# R5FSS0_CORE0_ECC_AGGR register map
Vendor: Texas Instruments
Peripheral module from a debugger description file (folder J7VCL).
Registers are 32-bit, access not given, reset 0x0 unless marked. A register's access mark holds for its fields unless they carry their own. Offsets are as the file gives them; lines under a group give offsets from that group; [hi:lo] are bit positions; {n}, {i} and the like mark numbered series; 'fields as' and 'values as' point back to an identical list; <NAME> marks a mode.

## R5FSS0_CORE0_ECC_AGGR
0x00 R5FSS_CPU0_REV ro reset 0x66A0E200 — Revision register.
  [31:0] REV — TI internal data. Identifies revision of peripheral.
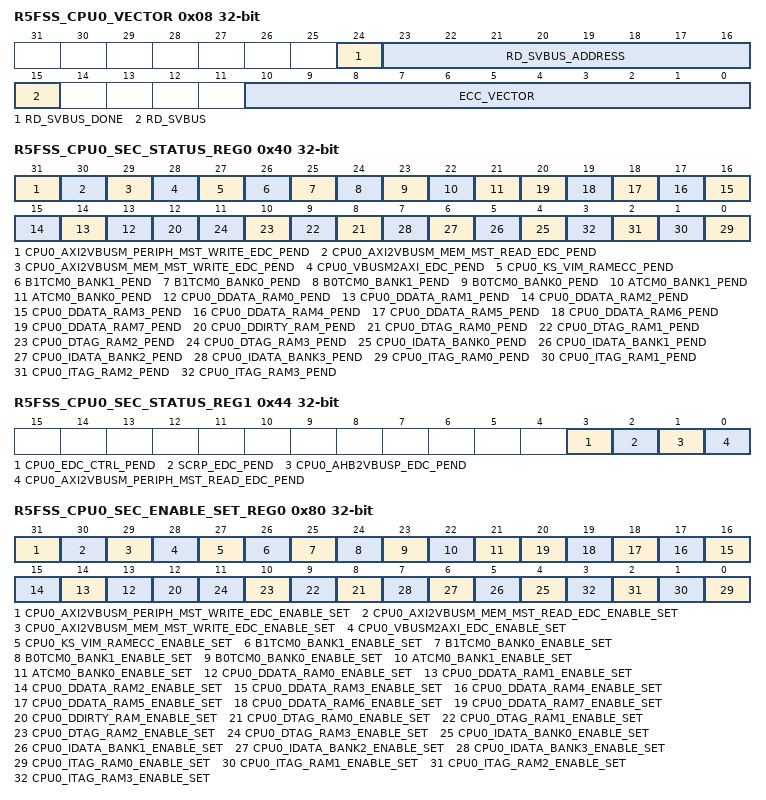
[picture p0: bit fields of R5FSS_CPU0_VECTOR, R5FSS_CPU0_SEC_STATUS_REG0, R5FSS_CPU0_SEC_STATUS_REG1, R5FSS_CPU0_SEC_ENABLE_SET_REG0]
0x08 R5FSS_CPU0_VECTOR — ECC vector register.
  [24] RD_SVBUS_DONE — Status to indicate if read on serial VBUS is complete, write of any value will clear this bit. (access RW1C)
  [23:16] RD_SVBUS_ADDRESS rw — Read address.
  [15] RD_SVBUS — Write 1 to trigger a read on the serial VBUS. (access RW1S)
  [10:0] ECC_VECTOR rw — Value written to select the corresponding ECC RAM for control or status.
0x0C R5FSS_CPU0_STAT ro reset 0x24 — Misc status register.
  [10:0] NUM_RAMS — Indicates the number of RAMS serviced by the ECC aggregator.
0x3C R5FSS_CPU0_SEC_EOI_REG — SEC EOI register. The EOI register is used to re-trigger the pulse interrupt signal to ensure that any nested interrupt events are serviced. The software interrupt handler must write to the EOI register at the end of the current interrupt processing routine, so that new events can re-trigger the pulse interrupt signal again. For level interrupt signals the EOI register is not functional and must not be used.
  [0] EOI_WR — EOI value. (access RW1S)
0x40 R5FSS_CPU0_SEC_STATUS_REG0 — SEC interrupt status register 0.
  [31] CPU0_AXI2VBUSM_PERIPH_MST_WRITE_EDC_PEND — Interrupt pending status for cpu0_axi2vbusm_periph_mst_write_edc_pend (access RW1S)
  [30] CPU0_AXI2VBUSM_MEM_MST_READ_EDC_PEND — Interrupt pending status for cpu0_axi2vbusm_mem_mst_read_edc_pend (access RW1S)
  [29] CPU0_AXI2VBUSM_MEM_MST_WRITE_EDC_PEND — Interrupt pending status for cpu0_axi2vbusm_mem_mst_write_edc_pend (access RW1S)
  [28] CPU0_VBUSM2AXI_EDC_PEND — Interrupt pending status for cpu0_vbusm2axi_edc_pend (access RW1S)
  [27] CPU0_KS_VIM_RAMECC_PEND — Interrupt pending status for cpu0_ks_vim_ramecc_pend (access RW1S)
  [26] B1TCM0_BANK1_PEND — Interrupt pending status for b1tcm0_bank1_pend (access RW1S)
  [25] B1TCM0_BANK0_PEND — Interrupt pending status for b1tcm0_bank0_pend (access RW1S)
  [24] B0TCM0_BANK1_PEND — Interrupt pending status for b0tcm0_bank1_pend (access RW1S)
  [23] B0TCM0_BANK0_PEND — Interrupt pending status for b0tcm0_bank0_pend (access RW1S)
  [22] ATCM0_BANK1_PEND — Interrupt pending status for atcm0_bank1_pend (access RW1S)
  [21] ATCM0_BANK0_PEND — Interrupt pending status for atcm0_bank0_pend (access RW1S)
  [n+13] CPU0_DDATA_RAM{n}_PEND (n=0..7) — Interrupt pending status for cpu0_ddata_ram{n}_pend (access RW1S)
  [12] CPU0_DDIRTY_RAM_PEND — Interrupt pending status for cpu0_ddirty_ram_pend (access RW1S)
  [n+8] CPU0_DTAG_RAM{n}_PEND (n=0..3) — Interrupt pending status for cpu0_dtag_ram{n}_pend (access RW1S)
  [n+4] CPU0_IDATA_BANK{n}_PEND (n=0..3) — Interrupt pending status for cpu0_idata_bank{n}_pend (access RW1S)
  [n] CPU0_ITAG_RAM{n}_PEND (n=0..3) — Interrupt pending status for cpu0_itag_ram{n}_pend (access RW1S)
0x44 R5FSS_CPU0_SEC_STATUS_REG1 — SEC interrupt status register 1.
  [3] CPU0_EDC_CTRL_PEND — Interrupt pending status for cpu0_edc_ctrl_pend (access RW1S)
  [2] SCRP_EDC_PEND — Interrupt pending status for scrp_edc_pend (access RW1S)
  [1] CPU0_AHB2VBUSP_EDC_PEND — Interrupt pending status for cpu0_ahb2vbusp_edc_pend (access RW1S)
  [0] CPU0_AXI2VBUSM_PERIPH_MST_READ_EDC_PEND — Interrupt pending status for cpu0_axi2vbusm_periph_mst_read_edc_pend (access RW1S)
0x80 R5FSS_CPU0_SEC_ENABLE_SET_REG0 — SEC Interrupt enable set register 0.
  [31] CPU0_AXI2VBUSM_PERIPH_MST_WRITE_EDC_ENABLE_SET — Interrupt enable set register for cpu0_axi2vbusm_periph_mst_write_edc_pend (access RW1S)
  [30] CPU0_AXI2VBUSM_MEM_MST_READ_EDC_ENABLE_SET — Interrupt enable set register for cpu0_axi2vbusm_mem_mst_read_edc_pend (access RW1S)
  [29] CPU0_AXI2VBUSM_MEM_MST_WRITE_EDC_ENABLE_SET — Interrupt enable set register for cpu0_axi2vbusm_mem_mst_write_edc_pend (access RW1S)
  [28] CPU0_VBUSM2AXI_EDC_ENABLE_SET — Interrupt enable set register for cpu0_vbusm2axi_edc_pend (access RW1S)
  [27] CPU0_KS_VIM_RAMECC_ENABLE_SET — Interrupt enable set register for cpu0_ks_vim_ramecc_pend (access RW1S)
  [26] B1TCM0_BANK1_ENABLE_SET — Interrupt enable set register for b1tcm0_bank1_pend (access RW1S)
  [25] B1TCM0_BANK0_ENABLE_SET — Interrupt enable set register for b1tcm0_bank0_pend (access RW1S)
  [24] B0TCM0_BANK1_ENABLE_SET — Interrupt enable set register for b0tcm0_bank1_pend (access RW1S)
  [23] B0TCM0_BANK0_ENABLE_SET — Interrupt enable set register for b0tcm0_bank0_pend (access RW1S)
  [22] ATCM0_BANK1_ENABLE_SET — Interrupt enable set register for atcm0_bank1_pend (access RW1S)
  [21] ATCM0_BANK0_ENABLE_SET — Interrupt enable set register for atcm0_bank0_pend (access RW1S)
  [n+13] CPU0_DDATA_RAM{n}_ENABLE_SET (n=0..7) — Interrupt enable set register for cpu0_ddata_ram{n}_pend (access RW1S)
  [12] CPU0_DDIRTY_RAM_ENABLE_SET — Interrupt enable set register for cpu0_ddirty_ram_pend (access RW1S)
  [n+8] CPU0_DTAG_RAM{n}_ENABLE_SET (n=0..3) — Interrupt enable set register for cpu0_dtag_ram{n}_pend (access RW1S)
  [n+4] CPU0_IDATA_BANK{n}_ENABLE_SET (n=0..3) — Interrupt enable set register for cpu0_idata_bank{n}_pend (access RW1S)
  [n] CPU0_ITAG_RAM{n}_ENABLE_SET (n=0..3) — Interrupt enable set register for cpu0_itag_ram{n}_pend (access RW1S)
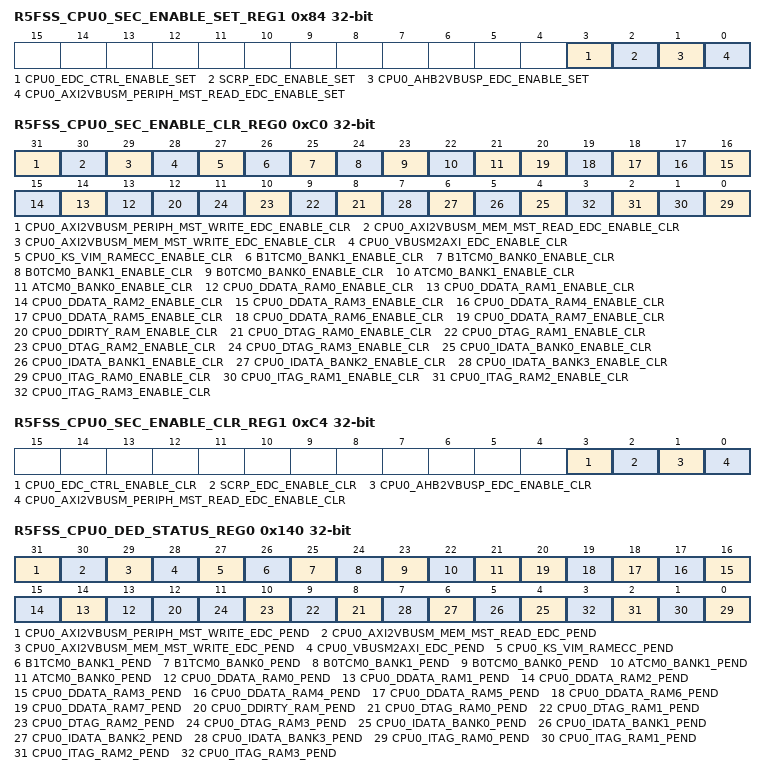
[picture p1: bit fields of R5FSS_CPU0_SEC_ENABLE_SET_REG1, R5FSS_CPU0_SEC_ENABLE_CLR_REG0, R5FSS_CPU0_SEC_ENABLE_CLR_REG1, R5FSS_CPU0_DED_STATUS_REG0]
0x84 R5FSS_CPU0_SEC_ENABLE_SET_REG1 — SEC interrupt enable set register 1.
  [3] CPU0_EDC_CTRL_ENABLE_SET — Interrupt enable set register for cpu0_edc_ctrl_pend (access RW1S)
  [2] SCRP_EDC_ENABLE_SET — Interrupt enable set register for scrp_edc_pend (access RW1S)
  [1] CPU0_AHB2VBUSP_EDC_ENABLE_SET — Interrupt enable set register for cpu0_ahb2vbusp_edc_pend (access RW1S)
  [0] CPU0_AXI2VBUSM_PERIPH_MST_READ_EDC_ENABLE_SET — Interrupt enable set register for cpu0_axi2vbusm_periph_mst_read_edc_pend (access RW1S)
0xC0 R5FSS_CPU0_SEC_ENABLE_CLR_REG0 — SEC interrupt enable clear register 0.
  [31] CPU0_AXI2VBUSM_PERIPH_MST_WRITE_EDC_ENABLE_CLR — Interrupt enable clear register for cpu0_axi2vbusm_periph_mst_write_edc_pend (access RW1C)
  [30] CPU0_AXI2VBUSM_MEM_MST_READ_EDC_ENABLE_CLR — Interrupt enable clear register for cpu0_axi2vbusm_mem_mst_read_edc_pend (access RW1C)
  [29] CPU0_AXI2VBUSM_MEM_MST_WRITE_EDC_ENABLE_CLR — Interrupt enable clear register for cpu0_axi2vbusm_mem_mst_write_edc_pend (access RW1C)
  [28] CPU0_VBUSM2AXI_EDC_ENABLE_CLR — Interrupt enable clear register for cpu0_vbusm2axi_edc_pend (access RW1C)
  [27] CPU0_KS_VIM_RAMECC_ENABLE_CLR — Interrupt enable clear register for cpu0_ks_vim_ramecc_pend (access RW1C)
  [26] B1TCM0_BANK1_ENABLE_CLR — Interrupt enable clear register for b1tcm0_bank1_pend (access RW1C)
  [25] B1TCM0_BANK0_ENABLE_CLR — Interrupt enable clear register for b1tcm0_bank0_pend (access RW1C)
  [24] B0TCM0_BANK1_ENABLE_CLR — Interrupt enable clear register for b0tcm0_bank1_pend (access RW1C)
  [23] B0TCM0_BANK0_ENABLE_CLR — Interrupt enable clear register for b0tcm0_bank0_pend (access RW1C)
  [22] ATCM0_BANK1_ENABLE_CLR — Interrupt enable clear register for atcm0_bank1_pend (access RW1C)
  [21] ATCM0_BANK0_ENABLE_CLR — Interrupt enable clear register for atcm0_bank0_pend (access RW1C)
  [n+13] CPU0_DDATA_RAM{n}_ENABLE_CLR (n=0..7) — Interrupt enable clear register for cpu0_ddata_ram{n}_pend (access RW1C)
  [12] CPU0_DDIRTY_RAM_ENABLE_CLR — Interrupt enable clear register for cpu0_ddirty_ram_pend (access RW1C)
  [n+8] CPU0_DTAG_RAM{n}_ENABLE_CLR (n=0..3) — Interrupt enable clear register for cpu0_dtag_ram{n}_pend (access RW1C)
  [n+4] CPU0_IDATA_BANK{n}_ENABLE_CLR (n=0..3) — Interrupt enable clear register for cpu0_idata_bank{n}_pend (access RW1C)
  [n] CPU0_ITAG_RAM{n}_ENABLE_CLR (n=0..3) — Interrupt enable clear register for cpu0_itag_ram{n}_pend (access RW1C)
0xC4 R5FSS_CPU0_SEC_ENABLE_CLR_REG1 — SEC interrupt enable clear register 1.
  [3] CPU0_EDC_CTRL_ENABLE_CLR — Interrupt enable clear register for cpu0_edc_ctrl_pend (access RW1C)
  [2] SCRP_EDC_ENABLE_CLR — Interrupt enable clear register for scrp_edc_pend (access RW1C)
  [1] CPU0_AHB2VBUSP_EDC_ENABLE_CLR — Interrupt enable clear register for cpu0_ahb2vbusp_edc_pend (access RW1C)
  [0] CPU0_AXI2VBUSM_PERIPH_MST_READ_EDC_ENABLE_CLR — Interrupt enable clear register for cpu0_axi2vbusm_periph_mst_read_edc_pend (access RW1C)
0x13C R5FSS_CPU0_DED_EOI_REG — DED EOI register. The EOI register is used to re-trigger the pulse interrupt signal to ensure that any nested interrupt events are serviced. The software interrupt handler must write to the EOI register at the end of the current interrupt processing routine, so that new events can re-trigger the pulse interrupt signal again. For level interrupt signals the EOI register is not functional and must not be used.
  [0] EOI_WR — EOI value. (access RW1S)
0x140 R5FSS_CPU0_DED_STATUS_REG0 — DED interrupt status register 0.
  fields as R5FSS_CPU0_SEC_STATUS_REG0
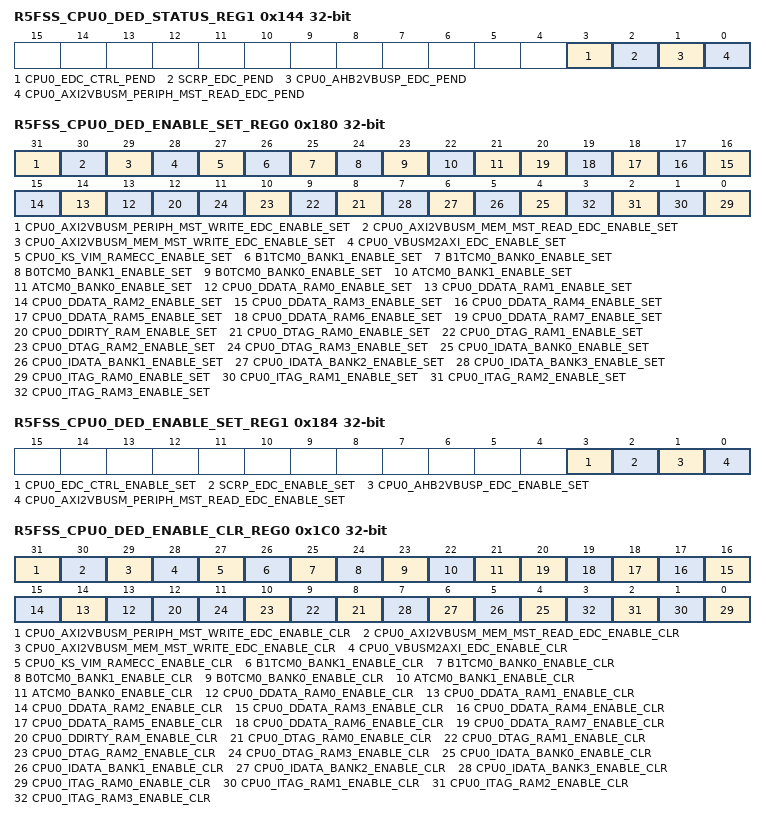
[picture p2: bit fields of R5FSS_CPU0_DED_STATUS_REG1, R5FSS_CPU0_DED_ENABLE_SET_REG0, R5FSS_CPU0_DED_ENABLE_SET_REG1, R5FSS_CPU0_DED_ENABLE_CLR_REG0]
0x144 R5FSS_CPU0_DED_STATUS_REG1 — DED interrupt status register 1.
  fields as R5FSS_CPU0_SEC_STATUS_REG1
0x180 R5FSS_CPU0_DED_ENABLE_SET_REG0 — DED interrupt enable set register 0.
  fields as R5FSS_CPU0_SEC_ENABLE_SET_REG0
0x184 R5FSS_CPU0_DED_ENABLE_SET_REG1 — DED interrupt enable set register 1.
  fields as R5FSS_CPU0_SEC_ENABLE_SET_REG1
0x1C0 R5FSS_CPU0_DED_ENABLE_CLR_REG0 — DED interrupt enable clear register 0.
  fields as R5FSS_CPU0_SEC_ENABLE_CLR_REG0
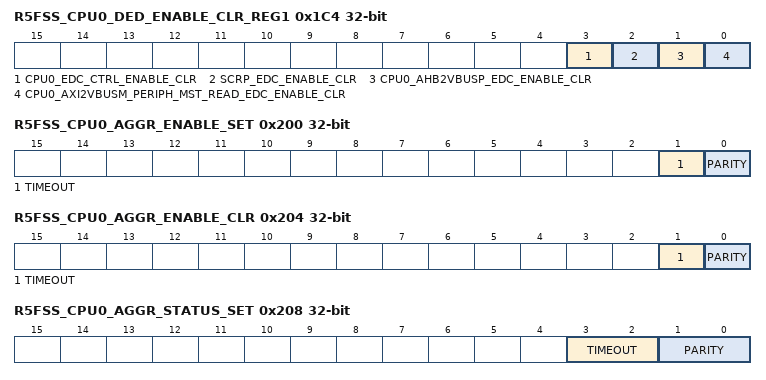
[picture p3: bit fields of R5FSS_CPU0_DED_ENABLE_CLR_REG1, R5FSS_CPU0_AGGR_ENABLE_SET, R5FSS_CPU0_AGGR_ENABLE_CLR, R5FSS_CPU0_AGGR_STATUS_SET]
0x1C4 R5FSS_CPU0_DED_ENABLE_CLR_REG1 — DED interrupt enable clear register 1.
  fields as R5FSS_CPU0_SEC_ENABLE_CLR_REG1
0x200 R5FSS_CPU0_AGGR_ENABLE_SET — AGGR interrupt enable set register.
  [1] TIMEOUT — interrupt enable set for svbus timeout errors (access RW1S)
  [0] PARITY — interrupt enable set for parity errors (access RW1S)
0x204 R5FSS_CPU0_AGGR_ENABLE_CLR — AGGR interrupt enable clear register.
  [1] TIMEOUT — interrupt enable clear for svbus timeout errors (access RW1C)
  [0] PARITY — interrupt enable clear for parity errors (access RW1C)
0x208 R5FSS_CPU0_AGGR_STATUS_SET access per field — AGGR interrupt status set register.
  [3:2] TIMEOUT rw — interrupt status set for svbus timeout errors
  [1:0] PARITY rw — interrupt status set for parity errors
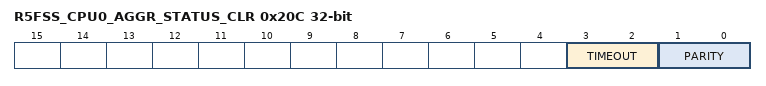
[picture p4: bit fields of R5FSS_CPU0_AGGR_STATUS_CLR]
0x20C R5FSS_CPU0_AGGR_STATUS_CLR access per field — AGGR interrupt status clear register.
  [3:2] TIMEOUT rw — interrupt status clear for svbus timeout errors
  [1:0] PARITY rw — interrupt status clear for parity errors
